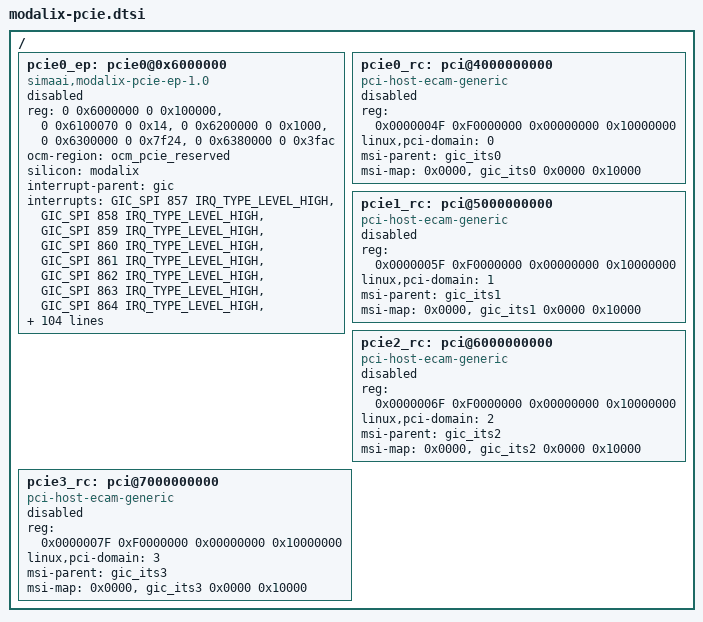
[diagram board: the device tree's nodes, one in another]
// SPDX-License-Identifier: (GPL-2.0+ OR MIT)
/*
 * Copyright (c) 2024 SiMa ai
 */

/ {
	pcie0_ep: pcie0@0x6000000 {
		compatible = "simaai,modalix-pcie-ep-1.0";
		reg = <0 0x6000000 0 0x100000>,	/* dbi */
			<0 0x6100070 0 0x14>,	/* dbi2 */
			<0 0x6200000 0 0x1000>, /* asr */
			<0 0x6300000 0 0x7f24>,	/* atu */
			<0 0x6380000 0 0x3fac>;	/* hdma */
		reg-names = "dbi", "dbi2", "asr", "atu", "hdma" ;
		ocm-region = <&ocm_pcie_reserved>;
		silicon = "modalix";
		interrupt-parent = <&gic>;
		interrupts = <GIC_SPI 857 IRQ_TYPE_LEVEL_HIGH>,
			<GIC_SPI 858 IRQ_TYPE_LEVEL_HIGH>,
			<GIC_SPI 859 IRQ_TYPE_LEVEL_HIGH>,
			<GIC_SPI 860 IRQ_TYPE_LEVEL_HIGH>,
			<GIC_SPI 861 IRQ_TYPE_LEVEL_HIGH>,
			<GIC_SPI 862 IRQ_TYPE_LEVEL_HIGH>,
			<GIC_SPI 863 IRQ_TYPE_LEVEL_HIGH>,
			<GIC_SPI 864 IRQ_TYPE_LEVEL_HIGH>,
			<GIC_SPI 865 IRQ_TYPE_LEVEL_HIGH>,
			<GIC_SPI 866 IRQ_TYPE_LEVEL_HIGH>,
			<GIC_SPI 867 IRQ_TYPE_LEVEL_HIGH>,
			<GIC_SPI 868 IRQ_TYPE_LEVEL_HIGH>,
			<GIC_SPI 869 IRQ_TYPE_LEVEL_HIGH>,
			<GIC_SPI 870 IRQ_TYPE_LEVEL_HIGH>,
			<GIC_SPI 871 IRQ_TYPE_LEVEL_HIGH>,
			<GIC_SPI 872 IRQ_TYPE_LEVEL_HIGH>,
			<GIC_SPI 873 IRQ_TYPE_LEVEL_HIGH>,
			<GIC_SPI 874 IRQ_TYPE_LEVEL_HIGH>,
			<GIC_SPI 875 IRQ_TYPE_LEVEL_HIGH>,
			<GIC_SPI 876 IRQ_TYPE_LEVEL_HIGH>,
			<GIC_SPI 877 IRQ_TYPE_LEVEL_HIGH>,
			<GIC_SPI 878 IRQ_TYPE_LEVEL_HIGH>,
			<GIC_SPI 879 IRQ_TYPE_LEVEL_HIGH>,
			<GIC_SPI 880 IRQ_TYPE_LEVEL_HIGH>,
			<GIC_SPI 881 IRQ_TYPE_LEVEL_HIGH>,
			<GIC_SPI 882 IRQ_TYPE_LEVEL_HIGH>,
			<GIC_SPI 883 IRQ_TYPE_LEVEL_HIGH>,
			<GIC_SPI 884 IRQ_TYPE_LEVEL_HIGH>,
			<GIC_SPI 885 IRQ_TYPE_LEVEL_HIGH>,
			<GIC_SPI 886 IRQ_TYPE_LEVEL_HIGH>,
			<GIC_SPI 887 IRQ_TYPE_LEVEL_HIGH>,
			<GIC_SPI 888 IRQ_TYPE_LEVEL_HIGH>,
			<GIC_SPI 889 IRQ_TYPE_LEVEL_HIGH>,
			<GIC_SPI 890 IRQ_TYPE_LEVEL_HIGH>,
			<GIC_SPI 891 IRQ_TYPE_LEVEL_HIGH>,
			<GIC_SPI 892 IRQ_TYPE_LEVEL_HIGH>,
			<GIC_SPI 893 IRQ_TYPE_LEVEL_HIGH>,
			<GIC_SPI 894 IRQ_TYPE_LEVEL_HIGH>,
			<GIC_SPI 895 IRQ_TYPE_LEVEL_HIGH>,
			<GIC_SPI 896 IRQ_TYPE_LEVEL_HIGH>,
			<GIC_SPI 897 IRQ_TYPE_LEVEL_HIGH>,
			<GIC_SPI 898 IRQ_TYPE_LEVEL_HIGH>,
			<GIC_SPI 899 IRQ_TYPE_LEVEL_HIGH>,
			<GIC_SPI 900 IRQ_TYPE_LEVEL_HIGH>,
			<GIC_SPI 901 IRQ_TYPE_LEVEL_HIGH>,
			<GIC_SPI 902 IRQ_TYPE_LEVEL_HIGH>,
			<GIC_SPI 903 IRQ_TYPE_LEVEL_HIGH>,
			<GIC_SPI 904 IRQ_TYPE_LEVEL_HIGH>,
			<GIC_SPI 481 IRQ_TYPE_LEVEL_HIGH>,
			<GIC_SPI 482 IRQ_TYPE_LEVEL_HIGH>,
			<GIC_SPI 483 IRQ_TYPE_LEVEL_HIGH>,
			<GIC_SPI 484 IRQ_TYPE_LEVEL_HIGH>,
			<GIC_SPI 485 IRQ_TYPE_LEVEL_HIGH>,
			<GIC_SPI 486 IRQ_TYPE_LEVEL_HIGH>,
			<GIC_SPI 487 IRQ_TYPE_LEVEL_HIGH>,
			<GIC_SPI 488 IRQ_TYPE_LEVEL_HIGH>,
			<GIC_SPI 489 IRQ_TYPE_LEVEL_HIGH>,
			<GIC_SPI 490 IRQ_TYPE_LEVEL_HIGH>,
			<GIC_SPI 491 IRQ_TYPE_LEVEL_HIGH>,
			<GIC_SPI 492 IRQ_TYPE_LEVEL_HIGH>,
			<GIC_SPI 493 IRQ_TYPE_LEVEL_HIGH>,
			<GIC_SPI 494 IRQ_TYPE_LEVEL_HIGH>,
			<GIC_SPI 495 IRQ_TYPE_LEVEL_HIGH>,
			<GIC_SPI 496 IRQ_TYPE_LEVEL_HIGH>,
			<GIC_SPI 497 IRQ_TYPE_LEVEL_HIGH>,
			<GIC_SPI 498 IRQ_TYPE_LEVEL_HIGH>,
			<GIC_SPI 499 IRQ_TYPE_LEVEL_HIGH>,
			<GIC_SPI 500 IRQ_TYPE_LEVEL_HIGH>,
			<GIC_SPI 501 IRQ_TYPE_LEVEL_HIGH>,
			<GIC_SPI 502 IRQ_TYPE_LEVEL_HIGH>,
			<GIC_SPI 503 IRQ_TYPE_LEVEL_HIGH>,
			<GIC_SPI 504 IRQ_TYPE_LEVEL_HIGH>,
			<GIC_SPI 505 IRQ_TYPE_LEVEL_HIGH>,
			<GIC_SPI 506 IRQ_TYPE_LEVEL_HIGH>,
			<GIC_SPI 507 IRQ_TYPE_LEVEL_HIGH>,
			<GIC_SPI 508 IRQ_TYPE_LEVEL_HIGH>,
			<GIC_SPI 509 IRQ_TYPE_LEVEL_HIGH>,
			<GIC_SPI 510 IRQ_TYPE_LEVEL_HIGH>,
			<GIC_SPI 511 IRQ_TYPE_LEVEL_HIGH>,
			<GIC_SPI 512 IRQ_TYPE_LEVEL_HIGH>,
			<GIC_SPI 513 IRQ_TYPE_LEVEL_HIGH>,
			<GIC_SPI 514 IRQ_TYPE_LEVEL_HIGH>,
			<GIC_SPI 515 IRQ_TYPE_LEVEL_HIGH>,
			<GIC_SPI 516 IRQ_TYPE_LEVEL_HIGH>,
			<GIC_SPI 517 IRQ_TYPE_LEVEL_HIGH>,
			<GIC_SPI 518 IRQ_TYPE_LEVEL_HIGH>,
			<GIC_SPI 519 IRQ_TYPE_LEVEL_HIGH>,
			<GIC_SPI 520 IRQ_TYPE_LEVEL_HIGH>,
			<GIC_SPI 521 IRQ_TYPE_LEVEL_HIGH>,
			<GIC_SPI 522 IRQ_TYPE_LEVEL_HIGH>,
			<GIC_SPI 523 IRQ_TYPE_LEVEL_HIGH>,
			<GIC_SPI 524 IRQ_TYPE_LEVEL_HIGH>,
			<GIC_SPI 525 IRQ_TYPE_LEVEL_HIGH>,
			<GIC_SPI 526 IRQ_TYPE_LEVEL_HIGH>,
			<GIC_SPI 527 IRQ_TYPE_LEVEL_HIGH>,
			<GIC_SPI 528 IRQ_TYPE_LEVEL_HIGH>,
			<GIC_SPI 529 IRQ_TYPE_LEVEL_HIGH>,
			<GIC_SPI 530 IRQ_TYPE_LEVEL_HIGH>,
			<GIC_SPI 531 IRQ_TYPE_LEVEL_HIGH>,
			<GIC_SPI 532 IRQ_TYPE_LEVEL_HIGH>,
			<GIC_SPI 533 IRQ_TYPE_LEVEL_HIGH>,
			<GIC_SPI 534 IRQ_TYPE_LEVEL_HIGH>,
			<GIC_SPI 535 IRQ_TYPE_LEVEL_HIGH>,
			<GIC_SPI 536 IRQ_TYPE_LEVEL_HIGH>,
			<GIC_SPI 537 IRQ_TYPE_LEVEL_HIGH>,
			<GIC_SPI 538 IRQ_TYPE_LEVEL_HIGH>,
			<GIC_SPI 539 IRQ_TYPE_LEVEL_HIGH>,
			<GIC_SPI 540 IRQ_TYPE_LEVEL_HIGH>,
			<GIC_SPI 541 IRQ_TYPE_LEVEL_HIGH>,
			<GIC_SPI 542 IRQ_TYPE_LEVEL_HIGH>,
			<GIC_SPI 543 IRQ_TYPE_LEVEL_HIGH>,
			<GIC_SPI 544 IRQ_TYPE_LEVEL_HIGH>;
		interrupt-names = "doorbell_0",
			"doorbell_1",
			"doorbell_2",
			"doorbell_3",
			"doorbell_4",
			"doorbell_5",
			"doorbell_6",
			"doorbell_7",
			"doorbell_8",
			"doorbell_9",
			"doorbell_10",
			"doorbell_11",
			"doorbell_12",
			"doorbell_13",
			"doorbell_14",
			"doorbell_15",
			"doorbell_16",
			"doorbell_17",
			"doorbell_18",
			"doorbell_19",
			"doorbell_20",
			"doorbell_21",
			"doorbell_22",
			"doorbell_23",
			"doorbell_24",
			"doorbell_25",
			"doorbell_26",
			"doorbell_27",
			"doorbell_28",
			"doorbell_29",
			"doorbell_30",
			"doorbell_31",
			"doorbell_32",
			"doorbell_33",
			"doorbell_34",
			"doorbell_35",
			"doorbell_36",
			"doorbell_37",
			"doorbell_38",
			"doorbell_39",
			"doorbell_40",
			"doorbell_41",
			"doorbell_42",
			"doorbell_43",
			"doorbell_44",
			"doorbell_45",
			"doorbell_46",
			"doorbell_47",
			"hdma_wch0",
			"hdma_wch1",
			"hdma_wch2",
			"hdma_wch3",
			"hdma_wch4",
			"hdma_wch5",
			"hdma_wch6",
			"hdma_wch7",
			"hdma_wch8",
			"hdma_wch9",
			"hdma_wch10",
			"hdma_wch11",
			"hdma_wch12",
			"hdma_wch13",
			"hdma_wch14",
			"hdma_wch15",
			"hdma_wch16",
			"hdma_wch17",
			"hdma_wch18",
			"hdma_wch19",
			"hdma_wch20",
			"hdma_wch21",
			"hdma_wch22",
			"hdma_wch23",
			"hdma_wch24",
			"hdma_wch25",
			"hdma_wch26",
			"hdma_wch27",
			"hdma_wch28",
			"hdma_wch29",
			"hdma_wch30",
			"hdma_wch31",
			"hdma_rch0",
			"hdma_rch1",
			"hdma_rch2",
			"hdma_rch3",
			"hdma_rch4",
			"hdma_rch5",
			"hdma_rch6",
			"hdma_rch7",
			"hdma_rch8",
			"hdma_rch9",
			"hdma_rch10",
			"hdma_rch11",
			"hdma_rch12",
			"hdma_rch13",
			"hdma_rch14",
			"hdma_rch15",
			"hdma_rch16",
			"hdma_rch17",
			"hdma_rch18",
			"hdma_rch19",
			"hdma_rch20",
			"hdma_rch21",
			"hdma_rch22",
			"hdma_rch23",
			"hdma_rch24",
			"hdma_rch25",
			"hdma_rch26",
			"hdma_rch27",
			"hdma_rch28",
			"hdma_rch29",
			"hdma_rch30",
			"hdma_rch31";
		status = "disabled";
	};

	pcie0_rc: pci@4000000000 {
		compatible = "pci-host-ecam-generic";
		device_type = "pci";
		reg = <0x0000004F 0xF0000000 0x00000000 0x10000000>;
		reg-names = "PCI ECAM";
		linux,pci-domain = <0>;
		#address-cells = <3>;
		#size-cells = <2>;
		ranges = <0x82000000 0x00000000 0x80000000 0x00000000 0x80000000 0x00000000 0x10000000>,
			 <0xC3000000 0x00000040 0x00000000 0x00000040 0x00000000 0x0000000F 0x00000000>;
		msi-parent = <&gic_its0>;
		msi-map = <0x0000 &gic_its0 0x0000 0x10000>;
		status = "disabled";
	};

	pcie1_rc: pci@5000000000 {
		compatible = "pci-host-ecam-generic";
		device_type = "pci";
		reg = <0x0000005F 0xF0000000 0x00000000 0x10000000>;
		reg-names = "PCI ECAM";
		linux,pci-domain = <1>;
		#address-cells = <3>;
		#size-cells = <2>;
		ranges = <0x82000000 0x00000000 0x90000000 0x00000000 0x90000000 0x00000000 0x10000000>,
			 <0xC3000000 0x00000050 0x00000000 0x00000050 0x00000000 0x0000000F 0x00000000>;
		msi-parent = <&gic_its1>;
		msi-map = <0x0000 &gic_its1 0x0000 0x10000>;
		status = "disabled";
	};

	pcie2_rc: pci@6000000000 {
		compatible = "pci-host-ecam-generic";
		device_type = "pci";
		reg = <0x0000006F 0xF0000000 0x00000000 0x10000000>;
		reg-names = "PCI ECAM";
		linux,pci-domain = <2>;
		#address-cells = <3>;
		#size-cells = <2>;
		ranges = <0x82000000 0x00000000 0xa0000000 0x00000000 0xa0000000 0x00000000 0x10000000>,
			 <0xC3000000 0x00000060 0x00000000 0x00000060 0x00000000 0x0000000F 0x00000000>;
		msi-parent = <&gic_its2>;
		msi-map = <0x0000 &gic_its2 0x0000 0x10000>;
		status = "disabled";
	};

	pcie3_rc: pci@7000000000 {
		compatible = "pci-host-ecam-generic";
		device_type = "pci";
		reg = <0x0000007F 0xF0000000 0x00000000 0x10000000>;
		reg-names = "PCI ECAM";
		linux,pci-domain = <3>;
		#address-cells = <3>;
		#size-cells = <2>;
		ranges = <0x82000000 0x00000000 0xb0000000 0x00000000 0xb0000000 0x00000000 0x10000000>,
			 <0xC3000000 0x00000070 0x00000000 0x00000070 0x00000000 0x0000000F 0x00000000>;
		msi-parent = <&gic_its3>;
		msi-map = <0x0000 &gic_its3 0x0000 0x10000>;
		status = "disabled";
	};
};
